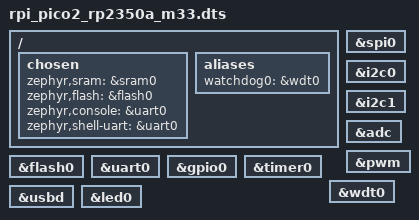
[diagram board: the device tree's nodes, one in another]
/*
 * Copyright (c) 2024 Andrew Featherstone
 *
 * SPDX-License-Identifier: Apache-2.0
 */

/dts-v1/;

/* The build system assumes that there's a cpucluster-specific file.
 *
 * This file provides composition of the device tree:
 * 1. The common features of the SoC
 * 2. Core-specific configuration.
 * 3. Board-specific configuration.
 */
#include <raspberrypi/rpi_pico/rp2350a.dtsi>
#include <raspberrypi/rpi_pico/m33.dtsi>

/* there's nothing specific to the Cortex-M33 cores vs the (not yet
 * implemented) Hazard3 cores.
 */
#include "rpi_pico2.dtsi"

/ {
	chosen {
		zephyr,sram = &sram0;
		zephyr,flash = &flash0;
		zephyr,console = &uart0;
		zephyr,shell-uart = &uart0;
	};

	aliases {
		watchdog0 = &wdt0;
	};
};

&flash0 {
	status = "okay";
};

&uart0 {
	status = "okay";
};

gpio0_lo: &gpio0 {
	status = "okay";
};

&spi0 {
	status = "okay";
};

&i2c0 {
	status = "okay";
};

&i2c1 {
	status = "okay";
};

&adc {
	status = "okay";
};

&pwm {
	status = "okay";
};

&timer0 {
	status = "okay";
};

&wdt0 {
	status = "okay";
};

zephyr_udc0: &usbd {
	status = "okay";
};

&led0 {
	status = "okay";
};
